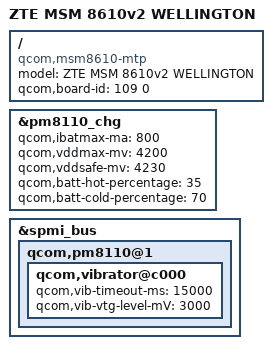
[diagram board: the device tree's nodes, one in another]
/* Copyright (c) 2013, The Linux Foundation. All rights reserved.
 *
 * This program is free software; you can redistribute it and/or modify
 * it under the terms of the GNU General Public License version 2 and
 * only version 2 as published by the Free Software Foundation.
 *
 * This program is distributed in the hope that it will be useful,
 * but WITHOUT ANY WARRANTY; without even the implied warranty of
 * MERCHANTABILITY or FITNESS FOR A PARTICULAR PURPOSE.  See the
 * GNU General Public License for more details.
 */

/dts-v1/;

/include/ "msm8610-v2-wellington.dtsi"
/include/ "msm8610-mtp-wellington.dtsi"
/include/ "msm8610-camera-sensor-cdp-mtp.dtsi"
/include/ "zte-msm8610-wellington.dtsi"

/ {
	model = "ZTE MSM 8610v2 WELLINGTON";
	compatible = "qcom,msm8610-mtp", "qcom,msm8610", "qcom,mtp";
	qcom,board-id = <109 0>;
};

&pm8110_chg {
	qcom,ibatmax-ma = <800>;
	qcom,vddmax-mv  = <4200>;
	qcom,vddsafe-mv = <4230>;
	qcom,batt-hot-percentage = <35>; /* 0- 45 degree*/
	qcom,batt-cold-percentage= <70>;
};

&spmi_bus {
	qcom,pm8110@1 {
		qcom,vibrator@c000 {
			status = "okay";
			qcom,vib-timeout-ms = <15000>;
			qcom,vib-vtg-level-mV = <3000>;/*P821A21_CRICKET 3v*/
		};
	};
};

